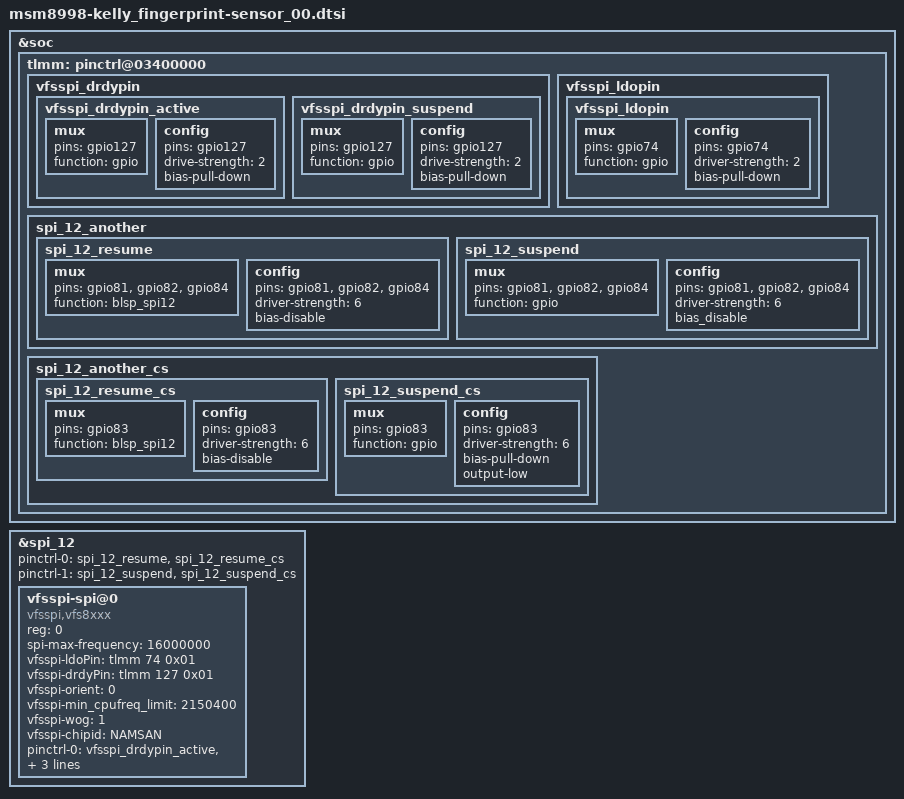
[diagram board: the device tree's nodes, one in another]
/* Copyright (c) 2013-2014, The Linux Foundation. All rights reserved.
 *
 * This program is free software; you can redistribute it and/or modify
 * it under the terms of the GNU General Public License version 2 and
 * only version 2 as published by the Free Software Foundation.
 *
 * This program is distributed in the hope that it will be useful,
 * but WITHOUT ANY WARRANTY; without even the implied warranty of
 * MERCHANTABILITY or FITNESS FOR A PARTICULAR PURPOSE.  See the
 * GNU General Public License for more details.
 */

&soc {
	tlmm: pinctrl@03400000 {
		vfsspi_drdypin {
			vfsspi_drdypin_active: vfsspi_drdypin_active {
				mux {
					pins = "gpio127";
					function = "gpio";
				};
				config {
					pins = "gpio127";
					drive-strength = <2>;
					bias-pull-down;
				};
			};

			vfsspi_drdypin_suspend: vfsspi_drdypin_suspend {
				mux {
					pins = "gpio127";
					function = "gpio";
				};
				config {
					pins = "gpio127";
					drive-strength = <2>;
					bias-pull-down;
				};
			};
		};
		vfsspi_ldopin {
			vfsspi_ldopin: vfsspi_ldopin {
				mux {
					pins = "gpio74";
					function = "gpio";
				};
				config {
					pins = "gpio74";
					driver-strength = <2>;
					bias-pull-down;
				};
			};
		};

		spi_12_another {
			spi_12_resume: spi_12_resume {
				mux {
					pins = "gpio81", "gpio82", "gpio84";
					function = "blsp_spi12";
				};
				config {
					pins = "gpio81", "gpio82", "gpio84";
					driver-strength = <6>;
					bias-disable;
				};
			};
			spi_12_suspend: spi_12_suspend {
				mux {
					pins = "gpio81", "gpio82", "gpio84";
					function = "gpio";
				};
				config {
					pins = "gpio81", "gpio82", "gpio84";
					driver-strength = <6>;
					bias_disable;
				};

			};
		};
		spi_12_another_cs {
			spi_12_resume_cs: spi_12_resume_cs {
				mux {
					pins = "gpio83";
					function = "blsp_spi12";
				};
				config {
					pins = "gpio83";
					driver-strength = <6>;
					bias-disable;
				};
			};
			spi_12_suspend_cs: spi_12_suspend_cs {
				mux {
					pins = "gpio83";
					function = "gpio";
				};
				config {
					pins = "gpio83";
					driver-strength = <6>;
					bias-pull-down;
					output-low;
				};

			};
		};
	};
};

&spi_12 {
	status = "ok";
	pinctrl-0 = <&spi_12_resume &spi_12_resume_cs>;
	pinctrl-1 = <&spi_12_suspend &spi_12_suspend_cs>;

	vfsspi-spi@0 {
		compatible = "vfsspi,vfs8xxx";
		reg = <0>;
		spi-max-frequency = <16000000>;
		vfsspi-ldoPin = <&tlmm 74 0x01>;
		vfsspi-drdyPin = <&tlmm 127 0x01>;

		vfsspi-orient = <0>;
		vfsspi-min_cpufreq_limit = <2150400>;
		vfsspi-wog = <1>;
		vfsspi-chipid = "NAMSAN";

		pinctrl-names = "default", "sleep", "idle";
		pinctrl-0 = <&vfsspi_drdypin_active &vfsspi_ldopin>;
		pinctrl-1 = <&vfsspi_drdypin_suspend>;
		pinctrl-2 = <&vfsspi_drdypin_active>;
	};
};
